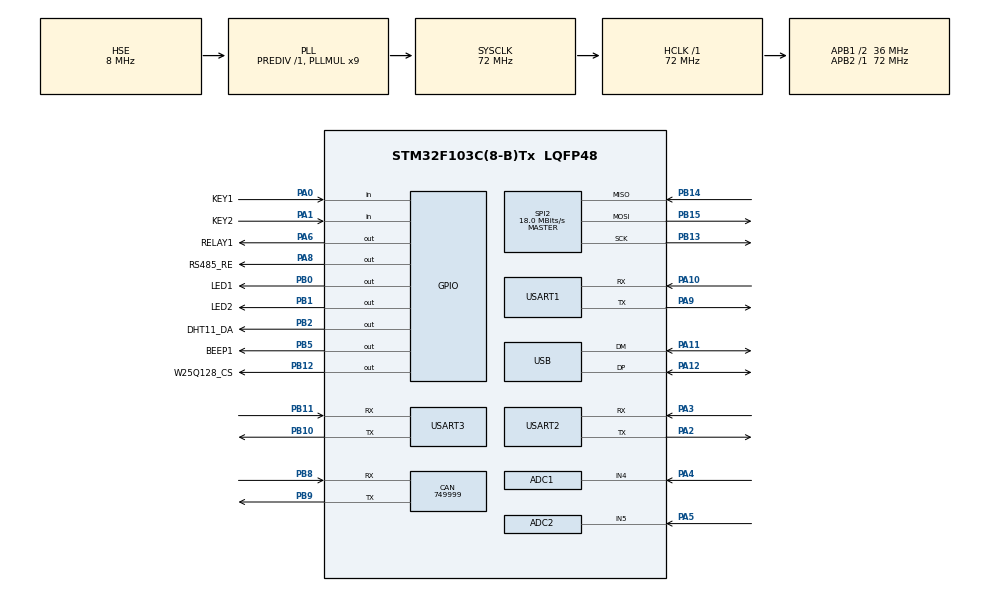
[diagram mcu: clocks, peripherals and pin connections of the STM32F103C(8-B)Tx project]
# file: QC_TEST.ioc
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ADC1.Channel-1\#ChannelRegularConversion=ADC_CHANNEL_4
ADC1.NbrOfConversionFlag=1
ADC1.Rank-1\#ChannelRegularConversion=1
ADC1.SamplingTime-1\#ChannelRegularConversion=ADC_SAMPLETIME_1CYCLE_5
ADC1.master=1
ADC2.Channel-2\#ChannelRegularConversion=ADC_CHANNEL_5
ADC2.NbrOfConversionFlag=1
ADC2.Rank-2\#ChannelRegularConversion=1
ADC2.SamplingTime-2\#ChannelRegularConversion=ADC_SAMPLETIME_1CYCLE_5
CAN.CalculateBaudRate=749999
CAN.CalculateTimeBit=1333
CAN.CalculateTimeQuantum=444.44444444444446
FREERTOS.Events01=myEvent01,Dynamic,NULL
FREERTOS.Mutexes01=myMutex01,Dynamic,NULL;myMutex02,Dynamic,NULL
FREERTOS.Queues01=myQueue01,16,uint16_t,0,Dynamic,NULL,NULL
FREERTOS.RecursiveMutexes01=myRecursiveMutex01,Dynamic,NULL
FREERTOS.Tasks01=defaultTask,24,128,StartDefaultTask,Default,NULL,Dynamic,NULL,NULL;myTask02,8,128,StartTask02,Default,NULL,Dynamic,NULL,NULL
FREERTOS.Timers01=myTimer01,Callback01,osTimerPeriodic,Default,NULL,Dynamic,NULL
FREERTOS.configUSE_NEWLIB_REENTRANT=1
Mcu.Family=STM32F1
Mcu.Name=STM32F103C(8-B)Tx
Mcu.Package=LQFP48
NVIC.PriorityGroup=NVIC_PRIORITYGROUP_4
NVIC.TIM2_IRQn=true\:15\:0\:false\:false\:true\:false\:false\:true\:true
NVIC.TimeBase=TIM2_IRQn
NVIC.TimeBaseIP=TIM2
PA0-WKUP.GPIO_Label=KEY1
PA0-WKUP.GPIO_PuPd=GPIO_PULLUP
PA0-WKUP.Signal=GPIO_Input
PA1.GPIO_Label=KEY2
PA1.GPIO_PuPd=GPIO_PULLUP
PA1.Signal=GPIO_Input
PA10.Mode=Asynchronous
PA10.Signal=USART1_RX
PA11.Mode=Device
PA11.Signal=USB_DM
PA12.Mode=Device
PA12.Signal=USB_DP
PA13.Mode=Serial_Wire
PA13.Signal=SYS_JTMS-SWDIO
PA14.Mode=Serial_Wire
PA14.Signal=SYS_JTCK-SWCLK
PA2.Mode=Asynchronous
PA2.Signal=USART2_TX
PA3.Mode=Asynchronous
PA3.Signal=USART2_RX
PA4.Signal=ADCx_IN4
PA5.Signal=ADCx_IN5
PA6.GPIO_Label=RELAY1
PA6.GPIO_ModeDefaultOutputPP=GPIO_MODE_OUTPUT_OD
PA6.GPIO_PuPd=GPIO_NOPULL
PA6.GPIO_Speed=GPIO_SPEED_FREQ_HIGH
PA6.PinState=GPIO_PIN_SET
PA6.Signal=GPIO_Output
PA8.GPIO_Label=RS485_RE
PA8.GPIO_PuPd=GPIO_NOPULL
PA8.GPIO_Speed=GPIO_SPEED_FREQ_HIGH
PA8.Signal=GPIO_Output
PA9.Mode=Asynchronous
PA9.Signal=USART1_TX
PB0.GPIO_Label=LED1
PB0.GPIO_ModeDefaultOutputPP=GPIO_MODE_OUTPUT_PP
PB0.GPIO_PuPd=GPIO_NOPULL
PB0.GPIO_Speed=GPIO_SPEED_FREQ_HIGH
PB0.PinState=GPIO_PIN_RESET
PB0.Signal=GPIO_Output
PB1.GPIO_Label=LED2
PB1.GPIO_Speed=GPIO_SPEED_FREQ_HIGH
PB1.PinState=GPIO_PIN_SET
PB1.Signal=GPIO_Output
PB10.Mode=Asynchronous
PB10.Signal=USART3_TX
PB11.Mode=Asynchronous
PB11.Signal=USART3_RX
PB12.GPIO_Label=W25Q128_CS
PB12.GPIO_PuPd=GPIO_PULLUP
PB12.GPIO_Speed=GPIO_SPEED_FREQ_HIGH
PB12.PinState=GPIO_PIN_SET
PB12.Signal=GPIO_Output
PB13.Mode=Full_Duplex_Master
PB13.Signal=SPI2_SCK
PB14.Mode=Full_Duplex_Master
PB14.Signal=SPI2_MISO
PB15.Mode=Full_Duplex_Master
PB15.Signal=SPI2_MOSI
PB2.GPIO_Label=DHT11_DA
PB2.GPIO_Speed=GPIO_SPEED_FREQ_HIGH
PB2.PinState=GPIO_PIN_SET
PB2.Signal=GPIO_Output
PB5.GPIO_Label=BEEP1
PB5.GPIO_Speed=GPIO_SPEED_FREQ_HIGH
PB5.PinState=GPIO_PIN_SET
PB5.Signal=GPIO_Output
PB8.Mode=CAN_Activate
PB8.Signal=CAN_RX
PB9.Mode=CAN_Activate
PB9.Signal=CAN_TX
PC14-OSC32_IN.Mode=LSE-External-Oscillator
PC14-OSC32_IN.Signal=RCC_OSC32_IN
PC15-OSC32_OUT.Mode=LSE-External-Oscillator
PC15-OSC32_OUT.Signal=RCC_OSC32_OUT
PD0-OSC_IN.Mode=HSE-External-Oscillator
PD0-OSC_IN.Signal=RCC_OSC_IN
PD1-OSC_OUT.Mode=HSE-External-Oscillator
PD1-OSC_OUT.Signal=RCC_OSC_OUT
ProjectManager.HeapSize=0x200
ProjectManager.StackSize=0x400
ProjectManager.TargetToolchain=STM32CubeIDE
RCC.ADCPresc=RCC_ADCPCLK2_DIV8
RCC.AHBFreq_Value=72000000
RCC.APB1CLKDivider=RCC_HCLK_DIV2
RCC.APB1Freq_Value=36000000
RCC.APB1TimFreq_Value=72000000
RCC.APB2Freq_Value=72000000
RCC.APB2TimFreq_Value=72000000
RCC.HCLKFreq_Value=72000000
RCC.PLLMUL=RCC_PLL_MUL9
RCC.PLLSourceVirtual=RCC_PLLSOURCE_HSE
RCC.RCC_MCOSource=RCC_MCO1SOURCE_HSE
RCC.RTCClockSelection=RCC_RTCCLKSOURCE_LSE
RCC.SYSCLKFreq_VALUE=72000000
RCC.SYSCLKSource=RCC_SYSCLKSOURCE_PLLCLK
RCC.USBFreq_Value=48000000
RCC.USBPrescaler=RCC_USBCLKSOURCE_PLL_DIV1_5
SH.ADCx_IN4.0=ADC1_IN4,IN4
SH.ADCx_IN5.0=ADC2_IN5,IN5
SPI2.CalculateBaudRate=18.0 MBits/s
SPI2.Direction=SPI_DIRECTION_2LINES
SPI2.Mode=SPI_MODE_MASTER
SPI2.VirtualType=VM_MASTER
USART1.VirtualMode=VM_ASYNC
USART2.VirtualMode=VM_ASYNC
USART3.VirtualMode=VM_ASYNC
VP_FREERTOS_VS_CMSIS_V2.Mode=CMSIS_V2
VP_RTC_VS_RTC_Activate.Mode=RTC_Enabled
VP_SYS_VS_tim2.Mode=TIM2
board=custom

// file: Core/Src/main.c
/* USER CODE BEGIN Header */
/**
  ******************************************************************************
  * @file           : main.c
  * @brief          : Main program body
  ******************************************************************************
  * @attention
  *
  * Copyright (c) 2021 STMicroelectronics.
  * All rights reserved.
  *
  * This software is licensed under terms that can be found in the LICENSE file
  * in the root directory of this software component.
  * If no LICENSE file comes with this software, it is provided AS-IS.
  *
  ******************************************************************************
  */
/* USER CODE END Header */
#include "main.h"
#include "cmsis_os.h"

/* USER CODE BEGIN Includes */
#include "../../icode/led/led.h"
#include "../../icode/key/key.h"
/* USER CODE END Includes */

ADC_HandleTypeDef hadc1;
ADC_HandleTypeDef hadc2;

CAN_HandleTypeDef hcan;

RTC_HandleTypeDef hrtc;

SPI_HandleTypeDef hspi2;

UART_HandleTypeDef huart1;
UART_HandleTypeDef huart2;
UART_HandleTypeDef huart3;

PCD_HandleTypeDef hpcd_USB_FS;

/* Definitions for defaultTask */
osThreadId_t defaultTaskHandle;
const osThreadAttr_t defaultTask_attributes = {
  .name = "defaultTask",
  .stack_size = 128 * 4,
  .priority = (osPriority_t) osPriorityNormal,
};
/* Definitions for myTask02 */
osThreadId_t myTask02Handle;
const osThreadAttr_t myTask02_attributes = {
  .name = "myTask02",
  .stack_size = 128 * 4,
  .priority = (osPriority_t) osPriorityLow,
};
/* Definitions for myQueue01 */
osMessageQueueId_t myQueue01Handle;
const osMessageQueueAttr_t myQueue01_attributes = {
  .name = "myQueue01"
};
/* Definitions for myTimer01 */
osTimerId_t myTimer01Handle;
const osTimerAttr_t myTimer01_attributes = {
  .name = "myTimer01"
};
/* Definitions for myMutex01 */
osMutexId_t myMutex01Handle;
const osMutexAttr_t myMutex01_attributes = {
  .name = "myMutex01"
};
/* Definitions for myMutex02 */
osMutexId_t myMutex02Handle;
const osMutexAttr_t myMutex02_attributes = {
  .name = "myMutex02"
};
/* Definitions for myRecursiveMutex01 */
osMutexId_t myRecursiveMutex01Handle;
const osMutexAttr_t myRecursiveMutex01_attributes = {
  .name = "myRecursiveMutex01",
  .attr_bits = osMutexRecursive,
};
/* Definitions for myEvent01 */
osEventFlagsId_t myEvent01Handle;
const osEventFlagsAttr_t myEvent01_attributes = {
  .name = "myEvent01"
};

void SystemClock_Config(void);
static void MX_GPIO_Init(void);
static void MX_RTC_Init(void);
static void MX_ADC1_Init(void);
static void MX_ADC2_Init(void);
static void MX_CAN_Init(void);
static void MX_SPI2_Init(void);
static void MX_USART1_UART_Init(void);
static void MX_USART2_UART_Init(void);
static void MX_USART3_UART_Init(void);
static void MX_USB_PCD_Init(void);
void StartDefaultTask(void *argument);
void StartTask02(void *argument);
void Callback01(void *argument);

int main(void)
{

  /* MCU Configuration--------------------------------------------------------*/

  /* Reset of all peripherals, Initializes the Flash interface and the Systick. */
  HAL_Init();

  /* Configure the system clock */
  SystemClock_Config();

  /* Initialize all configured peripherals */
  MX_GPIO_Init();
  MX_RTC_Init();
  MX_ADC1_Init();
  MX_ADC2_Init();
  MX_CAN_Init();
  MX_SPI2_Init();
  MX_USART1_UART_Init();
  MX_USART2_UART_Init();
  MX_USART3_UART_Init();
  MX_USB_PCD_Init();

  /* Init scheduler */
  osKernelInitialize();
  /* Create the mutex(es) */
  /* creation of myMutex01 */
  myMutex01Handle = osMutexNew(&myMutex01_attributes);

  /* creation of myMutex02 */
  myMutex02Handle = osMutexNew(&myMutex02_attributes);

  /* Create the recursive mutex(es) */
  /* creation of myRecursiveMutex01 */
  myRecursiveMutex01Handle = osMutexNew(&myRecursiveMutex01_attributes);

  /* Create the timer(s) */
  /* creation of myTimer01 */
  myTimer01Handle = osTimerNew(Callback01, osTimerPeriodic, NULL, &myTimer01_attributes);

  /* Create the queue(s) */
  /* creation of myQueue01 */
  myQueue01Handle = osMessageQueueNew (16, sizeof(uint16_t), &myQueue01_attributes);

  /* Create the thread(s) */
  /* creation of defaultTask */
  defaultTaskHandle = osThreadNew(StartDefaultTask, NULL, &defaultTask_attributes);

  /* creation of myTask02 */
  myTask02Handle = osThreadNew(StartTask02, NULL, &myTask02_attributes);

  /* creation of myEvent01 */
  myEvent01Handle = osEventFlagsNew(&myEvent01_attributes);

  /* Start scheduler */
  osKernelStart();

  /* We should never get here as control is now taken by the scheduler */
  /* Infinite loop */
  /* USER CODE BEGIN WHILE */
  while (1)
  {
//	  LED_1(1);//LED1灯控制（1点亮，0熄灭）
//	  LED_2(0);//LED2灯控制（1点亮，0熄灭）
//	  HAL_Delay(100);//在主循环里写入HAL库的毫秒级延时函数
//	  LED_1(0);//LED1灯控制（1点亮，0熄灭）
//	  LED_2(1);//LED2灯控制（1点亮，0熄灭）
//	  HAL_Delay(100);//在主循环里写入HAL库的毫秒级延时函数

	  if(KEY_1()) //按键KEY1判断为1时按键按下
	  {
		  LED_1(1);//LED1灯控制（1点亮，0熄灭）
		  LED_2(1);//LED2灯控制（1点亮，0熄灭）
	  }
	  if(KEY_2()) //按键KEY1判断为1时按键按下
	  {
		  LED_1(0);//LED1灯控制（1点亮，0熄灭）
		  LED_2(0);//LED2灯控制（1点亮，0熄灭）
	  }
    /* USER CODE END WHILE */

  }
}

void SystemClock_Config(void)
{
  RCC_OscInitTypeDef RCC_OscInitStruct = {0};
  RCC_ClkInitTypeDef RCC_ClkInitStruct = {0};
  RCC_PeriphCLKInitTypeDef PeriphClkInit = {0};

  /** Initializes the RCC Oscillators according to the specified parameters
  * in the RCC_OscInitTypeDef structure.
  */
  RCC_OscInitStruct.OscillatorType = RCC_OSCILLATORTYPE_HSE|RCC_OSCILLATORTYPE_LSE;
  RCC_OscInitStruct.HSEState = RCC_HSE_ON;
  RCC_OscInitStruct.HSEPredivValue = RCC_HSE_PREDIV_DIV1;
  RCC_OscInitStruct.LSEState = RCC_LSE_ON;
  RCC_OscInitStruct.HSIState = RCC_HSI_ON;
  RCC_OscInitStruct.PLL.PLLState = RCC_PLL_ON;
  RCC_OscInitStruct.PLL.PLLSource = RCC_PLLSOURCE_HSE;
  RCC_OscInitStruct.PLL.PLLMUL = RCC_PLL_MUL9;
  if (HAL_RCC_OscConfig(&RCC_OscInitStruct) != HAL_OK)
  {
    Error_Handler();
  }
  /** Initializes the CPU, AHB and APB buses clocks
  */
  RCC_ClkInitStruct.ClockType = RCC_CLOCKTYPE_HCLK|RCC_CLOCKTYPE_SYSCLK
                              |RCC_CLOCKTYPE_PCLK1|RCC_CLOCKTYPE_PCLK2;
  RCC_ClkInitStruct.SYSCLKSource = RCC_SYSCLKSOURCE_PLLCLK;
  RCC_ClkInitStruct.AHBCLKDivider = RCC_SYSCLK_DIV1;
  RCC_ClkInitStruct.APB1CLKDivider = RCC_HCLK_DIV2;
  RCC_ClkInitStruct.APB2CLKDivider = RCC_HCLK_DIV1;

  if (HAL_RCC_ClockConfig(&RCC_ClkInitStruct, FLASH_LATENCY_2) != HAL_OK)
  {
    Error_Handler();
  }
  PeriphClkInit.PeriphClockSelection = RCC_PERIPHCLK_RTC|RCC_PERIPHCLK_ADC
                              |RCC_PERIPHCLK_USB;
  PeriphClkInit.RTCClockSelection = RCC_RTCCLKSOURCE_LSE;
  PeriphClkInit.AdcClockSelection = RCC_ADCPCLK2_DIV8;
  PeriphClkInit.UsbClockSelection = RCC_USBCLKSOURCE_PLL_DIV1_5;
  if (HAL_RCCEx_PeriphCLKConfig(&PeriphClkInit) != HAL_OK)
  {
    Error_Handler();
  }
}

static void MX_ADC1_Init(void)
{

  ADC_ChannelConfTypeDef sConfig = {0};

  /** Common config
  */
  hadc1.Instance = ADC1;
  hadc1.Init.ScanConvMode = ADC_SCAN_DISABLE;
  hadc1.Init.ContinuousConvMode = DISABLE;
  hadc1.Init.DiscontinuousConvMode = DISABLE;
  hadc1.Init.ExternalTrigConv = ADC_SOFTWARE_START;
  hadc1.Init.DataAlign = ADC_DATAALIGN_RIGHT;
  hadc1.Init.NbrOfConversion = 1;
  if (HAL_ADC_Init(&hadc1) != HAL_OK)
  {
    Error_Handler();
  }
  /** Configure Regular Channel
  */
  sConfig.Channel = ADC_CHANNEL_4;
  sConfig.Rank = ADC_REGULAR_RANK_1;
  sConfig.SamplingTime = ADC_SAMPLETIME_1CYCLE_5;
  if (HAL_ADC_ConfigChannel(&hadc1, &sConfig) != HAL_OK)
  {
    Error_Handler();
  }

}

static void MX_ADC2_Init(void)
{

  ADC_ChannelConfTypeDef sConfig = {0};

  /** Common config
  */
  hadc2.Instance = ADC2;
  hadc2.Init.ScanConvMode = ADC_SCAN_DISABLE;
  hadc2.Init.ContinuousConvMode = DISABLE;
  hadc2.Init.DiscontinuousConvMode = DISABLE;
  hadc2.Init.ExternalTrigConv = ADC_SOFTWARE_START;
  hadc2.Init.DataAlign = ADC_DATAALIGN_RIGHT;
  hadc2.Init.NbrOfConversion = 1;
  if (HAL_ADC_Init(&hadc2) != HAL_OK)
  {
    Error_Handler();
  }
  /** Configure Regular Channel
  */
  sConfig.Channel = ADC_CHANNEL_5;
  sConfig.Rank = ADC_REGULAR_RANK_1;
  sConfig.SamplingTime = ADC_SAMPLETIME_1CYCLE_5;
  if (HAL_ADC_ConfigChannel(&hadc2, &sConfig) != HAL_OK)
  {
    Error_Handler();
  }

}

static void MX_CAN_Init(void)
{

  hcan.Instance = CAN1;
  hcan.Init.Prescaler = 16;
  hcan.Init.Mode = CAN_MODE_NORMAL;
  hcan.Init.SyncJumpWidth = CAN_SJW_1TQ;
  hcan.Init.TimeSeg1 = CAN_BS1_1TQ;
  hcan.Init.TimeSeg2 = CAN_BS2_1TQ;
  hcan.Init.TimeTriggeredMode = DISABLE;
  hcan.Init.AutoBusOff = DISABLE;
  hcan.Init.AutoWakeUp = DISABLE;
  hcan.Init.AutoRetransmission = DISABLE;
  hcan.Init.ReceiveFifoLocked = DISABLE;
  hcan.Init.TransmitFifoPriority = DISABLE;
  if (HAL_CAN_Init(&hcan) != HAL_OK)
  {
    Error_Handler();
  }

}

static void MX_RTC_Init(void)
{

  /** Initialize RTC Only
  */
  hrtc.Instance = RTC;
  hrtc.Init.AsynchPrediv = RTC_AUTO_1_SECOND;
  hrtc.Init.OutPut = RTC_OUTPUTSOURCE_ALARM;
  if (HAL_RTC_Init(&hrtc) != HAL_OK)
  {
    Error_Handler();
  }

}

static void MX_SPI2_Init(void)
{

  /* SPI2 parameter configuration*/
  hspi2.Instance = SPI2;
  hspi2.Init.Mode = SPI_MODE_MASTER;
  hspi2.Init.Direction = SPI_DIRECTION_2LINES;
  hspi2.Init.DataSize = SPI_DATASIZE_8BIT;
  hspi2.Init.CLKPolarity = SPI_POLARITY_LOW;
  hspi2.Init.CLKPhase = SPI_PHASE_1EDGE;
  hspi2.Init.NSS = SPI_NSS_SOFT;
  hspi2.Init.BaudRatePrescaler = SPI_BAUDRATEPRESCALER_2;
  hspi2.Init.FirstBit = SPI_FIRSTBIT_MSB;
  hspi2.Init.TIMode = SPI_TIMODE_DISABLE;
  hspi2.Init.CRCCalculation = SPI_CRCCALCULATION_DISABLE;
  hspi2.Init.CRCPolynomial = 10;
  if (HAL_SPI_Init(&hspi2) != HAL_OK)
  {
    Error_Handler();
  }

}

static void MX_USART1_UART_Init(void)
{

  huart1.Instance = USART1;
  huart1.Init.BaudRate = 115200;
  huart1.Init.WordLength = UART_WORDLENGTH_8B;
  huart1.Init.StopBits = UART_STOPBITS_1;
  huart1.Init.Parity = UART_PARITY_NONE;
  huart1.Init.Mode = UART_MODE_TX_RX;
  huart1.Init.HwFlowCtl = UART_HWCONTROL_NONE;
  huart1.Init.OverSampling = UART_OVERSAMPLING_16;
  if (HAL_UART_Init(&huart1) != HAL_OK)
  {
    Error_Handler();
  }

}

static void MX_USART2_UART_Init(void)
{

  huart2.Instance = USART2;
  huart2.Init.BaudRate = 115200;
  huart2.Init.WordLength = UART_WORDLENGTH_8B;
  huart2.Init.StopBits = UART_STOPBITS_1;
  huart2.Init.Parity = UART_PARITY_NONE;
  huart2.Init.Mode = UART_MODE_TX_RX;
  huart2.Init.HwFlowCtl = UART_HWCONTROL_NONE;
  huart2.Init.OverSampling = UART_OVERSAMPLING_16;
  if (HAL_UART_Init(&huart2) != HAL_OK)
  {
    Error_Handler();
  }

}

static void MX_USART3_UART_Init(void)
{

  huart3.Instance = USART3;
  huart3.Init.BaudRate = 115200;
  huart3.Init.WordLength = UART_WORDLENGTH_8B;
  huart3.Init.StopBits = UART_STOPBITS_1;
  huart3.Init.Parity = UART_PARITY_NONE;
  huart3.Init.Mode = UART_MODE_TX_RX;
  huart3.Init.HwFlowCtl = UART_HWCONTROL_NONE;
  huart3.Init.OverSampling = UART_OVERSAMPLING_16;
  if (HAL_UART_Init(&huart3) != HAL_OK)
  {
    Error_Handler();
  }

}

static void MX_USB_PCD_Init(void)
{

  hpcd_USB_FS.Instance = USB;
  hpcd_USB_FS.Init.dev_endpoints = 8;
  hpcd_USB_FS.Init.speed = PCD_SPEED_FULL;
  hpcd_USB_FS.Init.low_power_enable = DISABLE;
  hpcd_USB_FS.Init.lpm_enable = DISABLE;
  hpcd_USB_FS.Init.battery_charging_enable = DISABLE;
  if (HAL_PCD_Init(&hpcd_USB_FS) != HAL_OK)
  {
    Error_Handler();
  }

}

static void MX_GPIO_Init(void)
{
  GPIO_InitTypeDef GPIO_InitStruct = {0};

  /* GPIO Ports Clock Enable */
  __HAL_RCC_GPIOC_CLK_ENABLE();
  __HAL_RCC_GPIOD_CLK_ENABLE();
  __HAL_RCC_GPIOA_CLK_ENABLE();
  __HAL_RCC_GPIOB_CLK_ENABLE();

  /*Configure GPIO pin Output Level */
  HAL_GPIO_WritePin(RELAY1_GPIO_Port, RELAY1_Pin, GPIO_PIN_SET);

  /*Configure GPIO pin Output Level */
  HAL_GPIO_WritePin(LED1_GPIO_Port, LED1_Pin, GPIO_PIN_RESET);

  /*Configure GPIO pin Output Level */
  HAL_GPIO_WritePin(GPIOB, LED2_Pin|DHT11_DA_Pin|W25Q128_CS_Pin|BEEP1_Pin, GPIO_PIN_SET);

  /*Configure GPIO pin Output Level */
  HAL_GPIO_WritePin(RS485_RE_GPIO_Port, RS485_RE_Pin, GPIO_PIN_RESET);

  /*Configure GPIO pins : KEY1_Pin KEY2_Pin */
  GPIO_InitStruct.Pin = KEY1_Pin|KEY2_Pin;
  GPIO_InitStruct.Mode = GPIO_MODE_INPUT;
  GPIO_InitStruct.Pull = GPIO_PULLUP;
  HAL_GPIO_Init(GPIOA, &GPIO_InitStruct);

  /*Configure GPIO pin : RELAY1_Pin */
  GPIO_InitStruct.Pin = RELAY1_Pin;
  GPIO_InitStruct.Mode = GPIO_MODE_OUTPUT_OD;
  GPIO_InitStruct.Pull = GPIO_NOPULL;
  GPIO_InitStruct.Speed = GPIO_SPEED_FREQ_HIGH;
  HAL_GPIO_Init(RELAY1_GPIO_Port, &GPIO_InitStruct);

  /*Configure GPIO pins : LED1_Pin LED2_Pin DHT11_DA_Pin BEEP1_Pin */
  GPIO_InitStruct.Pin = LED1_Pin|LED2_Pin|DHT11_DA_Pin|BEEP1_Pin;
  GPIO_InitStruct.Mode = GPIO_MODE_OUTPUT_PP;
  GPIO_InitStruct.Pull = GPIO_NOPULL;
  GPIO_InitStruct.Speed = GPIO_SPEED_FREQ_HIGH;
  HAL_GPIO_Init(GPIOB, &GPIO_InitStruct);

  /*Configure GPIO pin : W25Q128_CS_Pin */
  GPIO_InitStruct.Pin = W25Q128_CS_Pin;
  GPIO_InitStruct.Mode = GPIO_MODE_OUTPUT_PP;
  GPIO_InitStruct.Pull = GPIO_PULLUP;
  GPIO_InitStruct.Speed = GPIO_SPEED_FREQ_HIGH;
  HAL_GPIO_Init(W25Q128_CS_GPIO_Port, &GPIO_InitStruct);

  /*Configure GPIO pin : RS485_RE_Pin */
  GPIO_InitStruct.Pin = RS485_RE_Pin;
  GPIO_InitStruct.Mode = GPIO_MODE_OUTPUT_PP;
  GPIO_InitStruct.Pull = GPIO_NOPULL;
  GPIO_InitStruct.Speed = GPIO_SPEED_FREQ_HIGH;
  HAL_GPIO_Init(RS485_RE_GPIO_Port, &GPIO_InitStruct);

}

void StartDefaultTask(void *argument)
{
  for(;;)
  {
    osDelay(1);
  }
}

void StartTask02(void *argument)
{
  for(;;)
  {
    osDelay(1);
  }
}

/* Callback01 function */
void Callback01(void *argument)
{
}

void HAL_TIM_PeriodElapsedCallback(TIM_HandleTypeDef *htim)
{
  if (htim->Instance == TIM2) {
    HAL_IncTick();
  }
}

void Error_Handler(void)
{
  __disable_irq();
  while (1)
  {
  }
}
